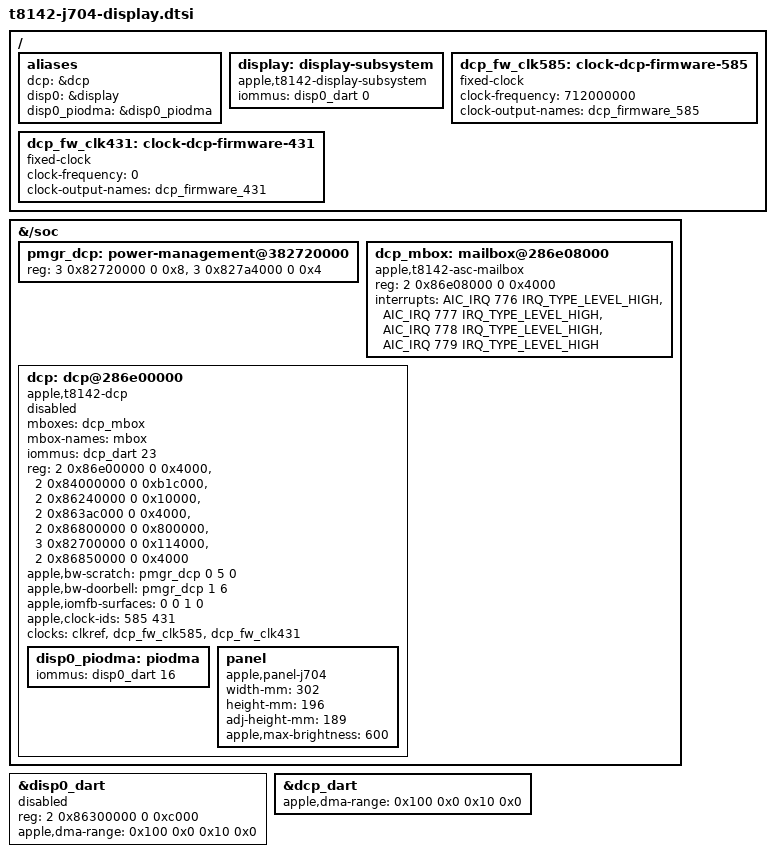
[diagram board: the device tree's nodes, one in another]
// SPDX-License-Identifier: GPL-2.0+ OR MIT
/*
 * J704 internal display pipeline: the DCP coprocessor and its DARTs.
 *
 * The bootloader leaves DCP running with its firmware mapped through
 * locked DART tables. The loader reserves those mappings and enables the
 * nodes below; Linux attaches to the running coprocessor without resetting
 * it. Resources were read from this machine's Apple Device Tree.
 */

/ {
	aliases {
		dcp = &dcp;
		disp0 = &display;
		disp0_piodma = &disp0_piodma;
	};

	display: display-subsystem {
		compatible = "apple,t8142-display-subsystem", "apple,display-subsystem";
		/* disp0_dart must be first since it is locked */
		iommus = <&disp0_dart 0>;
		/* generate phandle explicitly for use in loader */
		phandle = <&display>;
	};
};

&{/soc} {
	pmgr_dcp: power-management@382720000 {
		reg = <3 0x82720000 0 0x8>, <3 0x827a4000 0 0x4>;
		reg-names = "dcp-bw-scratch", "dcp-bw-doorbell";
		#apple,bw-scratch-cells = <3>;
		#apple,bw-doorbell-cells = <2>;
	};

	dcp_mbox: mailbox@286e08000 {
		compatible = "apple,t8142-asc-mailbox", "apple,asc-mailbox-v4";
		reg = <2 0x86e08000 0 0x4000>;
		interrupts = <AIC_IRQ 776 IRQ_TYPE_LEVEL_HIGH>,
			     <AIC_IRQ 777 IRQ_TYPE_LEVEL_HIGH>,
			     <AIC_IRQ 778 IRQ_TYPE_LEVEL_HIGH>,
			     <AIC_IRQ 779 IRQ_TYPE_LEVEL_HIGH>;
		interrupt-names = "send-empty", "send-not-empty",
				  "recv-empty", "recv-not-empty";
		#mbox-cells = <0>;
	};

	dcp: dcp@286e00000 {
		compatible = "apple,t8142-dcp", "apple,dcp";
		mboxes = <&dcp_mbox>;
		mbox-names = "mbox";
		iommus = <&dcp_dart 23>;
		reg-names = "coproc", "disp-0", "disp-1", "disp-2",
			    "disp-3", "disp-4", "iop-vbar";
		reg = <2 0x86e00000 0 0x4000>,
		      <2 0x84000000 0 0xb1c000>,
		      <2 0x86240000 0 0x10000>,
		      <2 0x863ac000 0 0x4000>,
		      <2 0x86800000 0 0x800000>,
		      <3 0x82700000 0 0x114000>,
		      <2 0x86850000 0 0x4000>;
		apple,bw-scratch = <&pmgr_dcp 0 5 0>;
		apple,bw-doorbell = <&pmgr_dcp 1 6>;
		/* Scan out the primary plane on IOMFB surface 2. */
		apple,iomfb-surfaces = <0 0 1 0>;
		/*
		 * Firmware 27 (DCP_FIRMWARE_V_27_0) asks for its provider clocks by
		 * index into /arm-io/disp0 clock-ids, in this order: firmware-0 and
		 * firmware-1. The J704 ADT has the same ids as the J813's.
		 */
		apple,clock-ids = <585 431>;
		clocks = <&clkref>, <&dcp_fw_clk585>, <&dcp_fw_clk431>;
		clock-names = "clock-154", "firmware-0", "firmware-1";
		/* generate phandle explicitly for use in loader */
		phandle = <&dcp>;
		status = "disabled";
		/* required bus properties for 'piodma' subdevice */
		#address-cells = <2>;
		#size-cells = <2>;

		disp0_piodma: piodma {
			iommus = <&disp0_dart 16>;
			phandle = <&disp0_piodma>;
		};

		/*
		 * 14.2" mini-LED, 3024x1964 (1890 below the notch, which the
		 * loader passes as apple,notch-height). Makes the connector eDP
		 * and gives the DCP a backlight to drive.
		 */
		panel: panel {
			compatible = "apple,panel-j704", "apple,panel-mini-led",
				     "apple,panel";
			width-mm = <302>;
			height-mm = <196>;
			adj-height-mm = <189>;
			apple,max-brightness = <600>;
		};
	};
};

/*
 * Scanout and PIODMA share the first register window (as in the J813 tree).
 * The boot loader's T8142 display handoff admits a stream only on a DART
 * with a single register window and refuses the whole display otherwise.
 */
&disp0_dart {
	reg = <2 0x86300000 0 0xc000>;
	apple,dma-range = <0x100 0x0 0x10 0x0>;
	status = "disabled";
};

&dcp_dart {
	apple,dma-range = <0x100 0x0 0x10 0x0>;
	status = "okay";
};

/ {
	/*
	 * The DCP firmware's clocks 585 and 431 (/arm-io/disp0 clock-ids), as on
	 * the J813: firmware 27 reads only 585, as its minimum pixel clock. 712 MHz
	 * is entry 0x49 of this machine's ADT clock-frequencies, the one 585's low
	 * byte names (the same value as on the J813). 431 is never asked for.
	 */
	dcp_fw_clk585: clock-dcp-firmware-585 {
		compatible = "fixed-clock";
		#clock-cells = <0>;
		clock-frequency = <712000000>;
		clock-output-names = "dcp_firmware_585";
	};

	dcp_fw_clk431: clock-dcp-firmware-431 {
		compatible = "fixed-clock";
		#clock-cells = <0>;
		clock-frequency = <0>;
		clock-output-names = "dcp_firmware_431";
	};
};
